# GD32A72_A74x register map
File version: 1.0
CPU: CM7 r2p1, little endian, MPU, FPU, DSP, 4 interrupt priority bits
Registers are 32-bit, read-write, reset 0x0 unless marked. A register's access mark holds for its fields unless they carry their own. Offsets are from the block's base; [hi:lo] are bit positions; {n}, {i} and the like mark numbered series; 'fields as' and 'values as' point back to an identical list.

## FMU — Fault management unit
Base 0x40023400
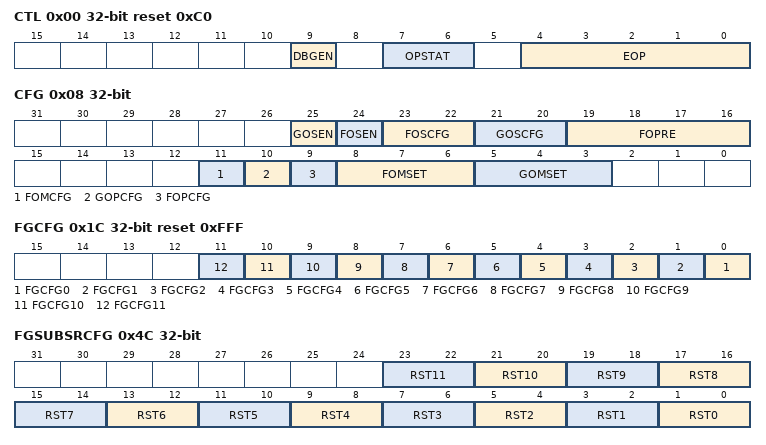
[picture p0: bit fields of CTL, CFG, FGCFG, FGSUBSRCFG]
0x00 CTL access per field reset 0xC0 — Control register
  [9] DBGEN rw — FMU debug mode enable bit
  [7:6] OPSTAT ro — Operation status bits
  [4:0] EOP rw — Execute operation bits
0x04 CTLKEY — Control key register
  [31:0] CTLKEY — Unlock operation control key
0x08 CFG — Configuration register
  [25] GOSEN — General output pin (GFpin) signals enable bit
  [24] FOSEN — Fault output pin (FFpin) signals enable bit
  [23:22] FOSCFG — Fault output pin (FFpin) signals configuration bits
  [21:20] GOSCFG — General output pin signals configuration bits
  [19:16] FOPRE — Fault output pin signals time switching clock prescaler configuration bits
  [11] FOMCFG — Fault output pin (FFpin) signals work mode configuration bit
  [10] GOPCFG — General fault output pin (GFIO) signal polarity configuration bit
  [9] FOPCFG — Fault output pin (FFpin) signals polarity configuration bit
  [8:6] FOMSET — Fault output pin (FFpin) signals work mode set bits
  [5:3] GOMSET — General output pin (GFpin) signals work mode set bits
0x1C FGCFG reset 0xFFF — FG configuration register
  [n] FGCFG{n} (n=0..11) — FG fault recovery type configuration bit {n}
0x4C FGSUBSRCFG — FG subsystem reset configuration register
  [2n+1:2n] RST{n} (n=0..11) — FG subsystem reset reaction configuration {n} bits
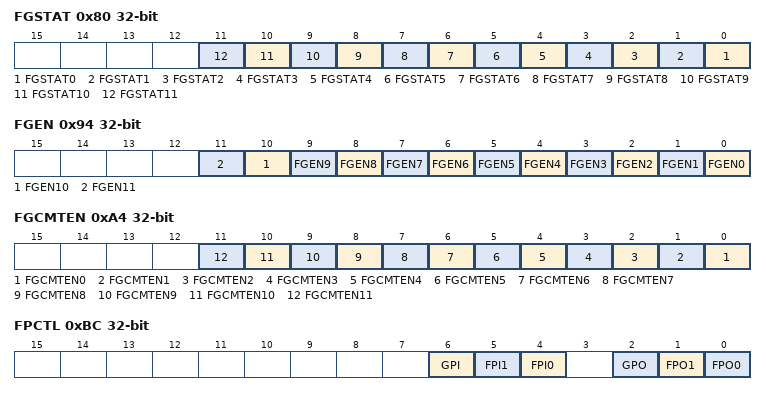
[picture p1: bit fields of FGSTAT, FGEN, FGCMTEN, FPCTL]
0x80 FGSTAT — FG status register
  [n] FGSTAT{n} (n=0..11) — FG fault status bit {n}
0x90 FGKEY
  [31:0] FGKEY — Unlock FG status register key
0x94 FGEN — FG enable register
  [n] FGEN{n} (n=0..11) — FG enable bit {n}
0xA4 FGCMTEN — FG CAUTION work mode timeout enable register
  [n] FGCMTEN{n} (n=0..11) — FG fault caution work mode timeout enable bit {n}
0xB4 FGCMTVAL reset 0x3A980 — FG CAUTION work mode timeout value register
  [31:0] FGCMTVAL — FG caution work mode timeout value bits
0xB8 IMTVAL reset 0x5 — INIT work mode timeout value register
  [2:0] IMTVAL — FMU INIT work mode timeout value bits
0xBC FPCTL access per field — Fault pin control register
  [6] GPI ro — GFpin signal input status
  [5] FPI1 ro — FFpin1 signal input status
  [4] FPI0 ro — FFpin0 signal input status
  [2] GPO rw — GFpin output signal configuration bit
  [1] FPO1 rw — FFpin1 output signal configuration bit
  [0] FPO0 rw — FFpin0 output signal configuration bit
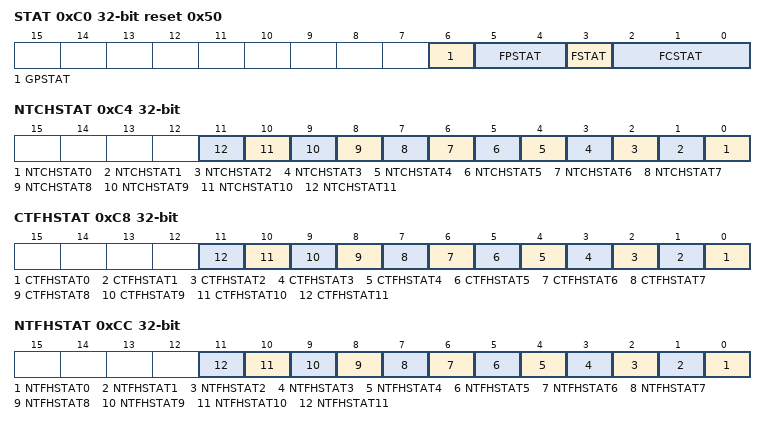
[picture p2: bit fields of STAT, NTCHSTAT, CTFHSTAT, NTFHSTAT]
0xC0 STAT ro reset 0x50 — Status register
  [6] GPSTAT — GFpin signal states (fault drive signals)
  [5:4] FPSTAT — FFpin signal states
  [3] FSTAT — FMU faulty state bit
  [2:0] FCSTAT — FMU current work mode state bits
0xC4 NTCHSTAT ro — Normal transform to caution hold status register
  [n] NTCHSTAT{n} (n=0..11) — Normal transform to caution work mode hold status bit {n}
0xC8 CTFHSTAT ro — CAUTION transform to FAULT work mode hold status register
  [n] CTFHSTAT{n} (n=0..11) — CAUTION transform to FAULT work mode hold status bit {n}
0xCC NTFHSTAT ro — NORMAL transform to FAULT work mode hold status register
  [n] NTFHSTAT{n} (n=0..11) — normal transform to fault work mode hold status bit {n}
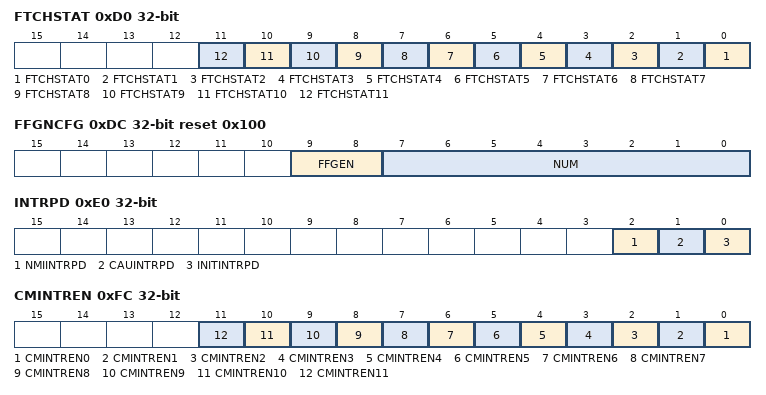
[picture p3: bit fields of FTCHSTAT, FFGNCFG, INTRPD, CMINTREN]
0xD0 FTCHSTAT ro — FAULT transform to CAUTION work mode hold status register
  [n] FTCHSTAT{n} (n=0..11) — FAULT transform to CAUTION work mode hold status bit {n}
0xDC FFGNCFG access per field reset 0x100 — Fake FG fault number configuration register
  [9:8] FFGEN rw — Fake FG fault enable configure bits
  [7:0] NUM wo — Injection fake FG fault number configuration bits
0xE0 INTRPD access per field — Interrupt pending register
  [2] NMIINTRPD ro — NMI interrupt request pending bit
  [1] CAUINTRPD ro — CATION work mode request pending bit
  [0] INITINTRPD rw — INIT work mode timeout request pending bit
0xE4 IMTINTREN — INIT work mode timeout request enable register
  [0] INITTIE — INIT work mode timeout enable bit
0xF0 TCLOCK — Temporary configuration lock register
  [8:0] TCLK — INIT work mode transition temporary lock bits
0xF4 PCLOCK — Permanent configuration lock register
  [8:0] PCLK — INIT work mode transition permanent lock bits
0xF8 FOT — Fault output timer register
  [13:0] FOT — Fault output(FFpin) timer configure bits
0xFC CMINTREN — FG CAUTION work mode interrupt request enable register
  [n] CMINTREN{n} (n=0..11) — CAUTION work mode interrupt request enable bit {n}
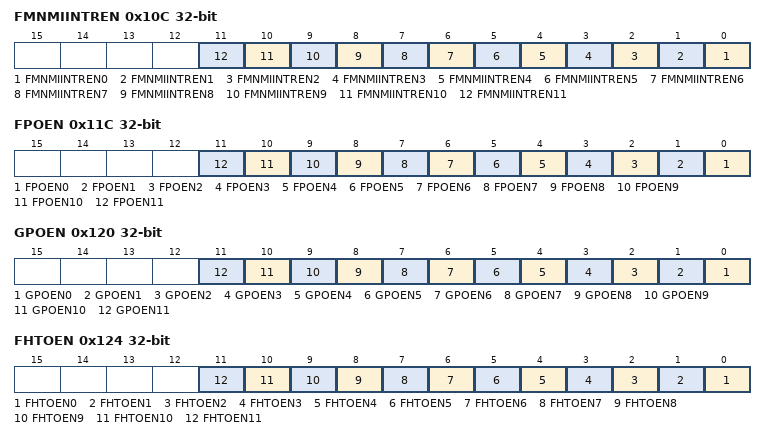
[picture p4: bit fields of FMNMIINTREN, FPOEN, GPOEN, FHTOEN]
0x10C FMNMIINTREN — FG FAULT work mode NMI interrupt request enable register
  [n] FMNMIINTREN{n} (n=0..11) — FAULT work mode NMI interrupt request enable bit {n}
0x11C FPOEN — FG FFpin output enable register
  [n] FPOEN{n} (n=0..11) — FAULT work mode FFpin signaling enable bit {n}
0x120 GPOEN — FG GFpin output enable register
  [n] GPOEN{n} (n=0..11) — FAULT work mode GFpin signaling enable bit {n}
0x124 FHTOEN — Fault holding timer output enable register
  [n] FHTOEN{n} (n=0..11) — FAULT work mode holding timer output enable bit {n}
0x12C CMCNT ro — FG CAUTION work mode counter register
  [31:0] CMCNT — CAUTION work mode timer count configure bits
0x134 IMCNT — FG INIT work mode counter register
  [31:0] IMCNT — INIT work mode timer count configure bits
0x138 FOCNT ro — Fault output counter register
  [31:0] FOCNT — Fault output timer count configure bits
0x13C GOCNT ro — General Fault output counter register
  [31:0] GOCNT — GFIO fault output timer counter
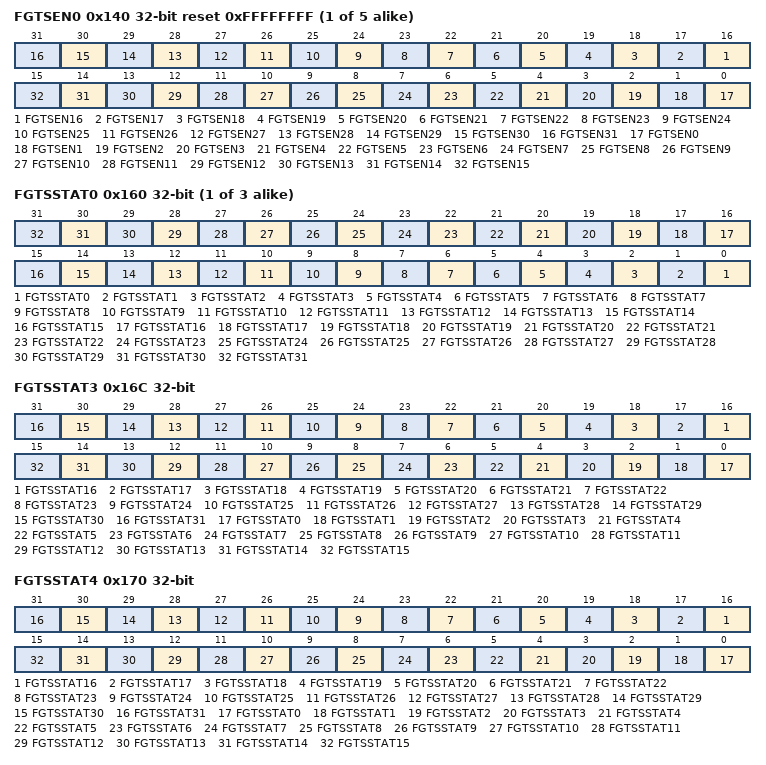
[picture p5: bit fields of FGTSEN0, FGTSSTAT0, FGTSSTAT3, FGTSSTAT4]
{0x140+4i} FGTSEN{i} reset 0xFFFFFFFF (i=0..4) — FG trigger source enable register
  [n] FGTSEN{n} (n=16..31) — fg trigger source enable bit {n}
  [n] FGTSEN{n} (n=0..15) — FG trigger source enable bit {n}
{0x160+4i} FGTSSTAT{i} (i=0..2) — FG trigger source status register
  [n] FGTSSTAT{n} (n=0..31) — fg trigger source status bit {n}
0x16C FGTSSTAT3 — FG trigger source status register
  [n] FGTSSTAT{n} (n=16..31) — fg trigger source status bit {n}
  [n] FGTSSTAT{n} (n=0..15) — FG trigger source status bit {n}
0x170 FGTSSTAT4 — FG trigger source status register
  fields as FGTSSTAT3
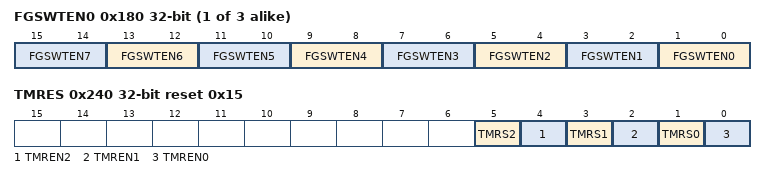
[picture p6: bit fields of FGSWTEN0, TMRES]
{0x180+4i} FGSWTEN{i} (i=0..2) — FG software triggered fault enable register
  [2n+1:2n] FGSWTEN{n} (n=0..7) — software triggered fault enable bit {n}
0x240 TMRES reset 0x15 — TMR enable and status register
  [5] TMRS2 — fmu_fgcfg and fmu_fgen registers tmr error status (tmr error status bit 2)
  [4] TMREN2 — tmr error output enable bit 2
  [3] TMRS1 — fosen, foscfg[1:0], gosen and goscfg[1:0] bits tmr error status (tmr error status bit 1)
  [2] TMREN1 — tmr error output enable bit 1
  [1] TMRS0 — dbgen register tmr error status (tmr error status bit 0)
  [0] TMREN0 — tmr error output enable bit 0
